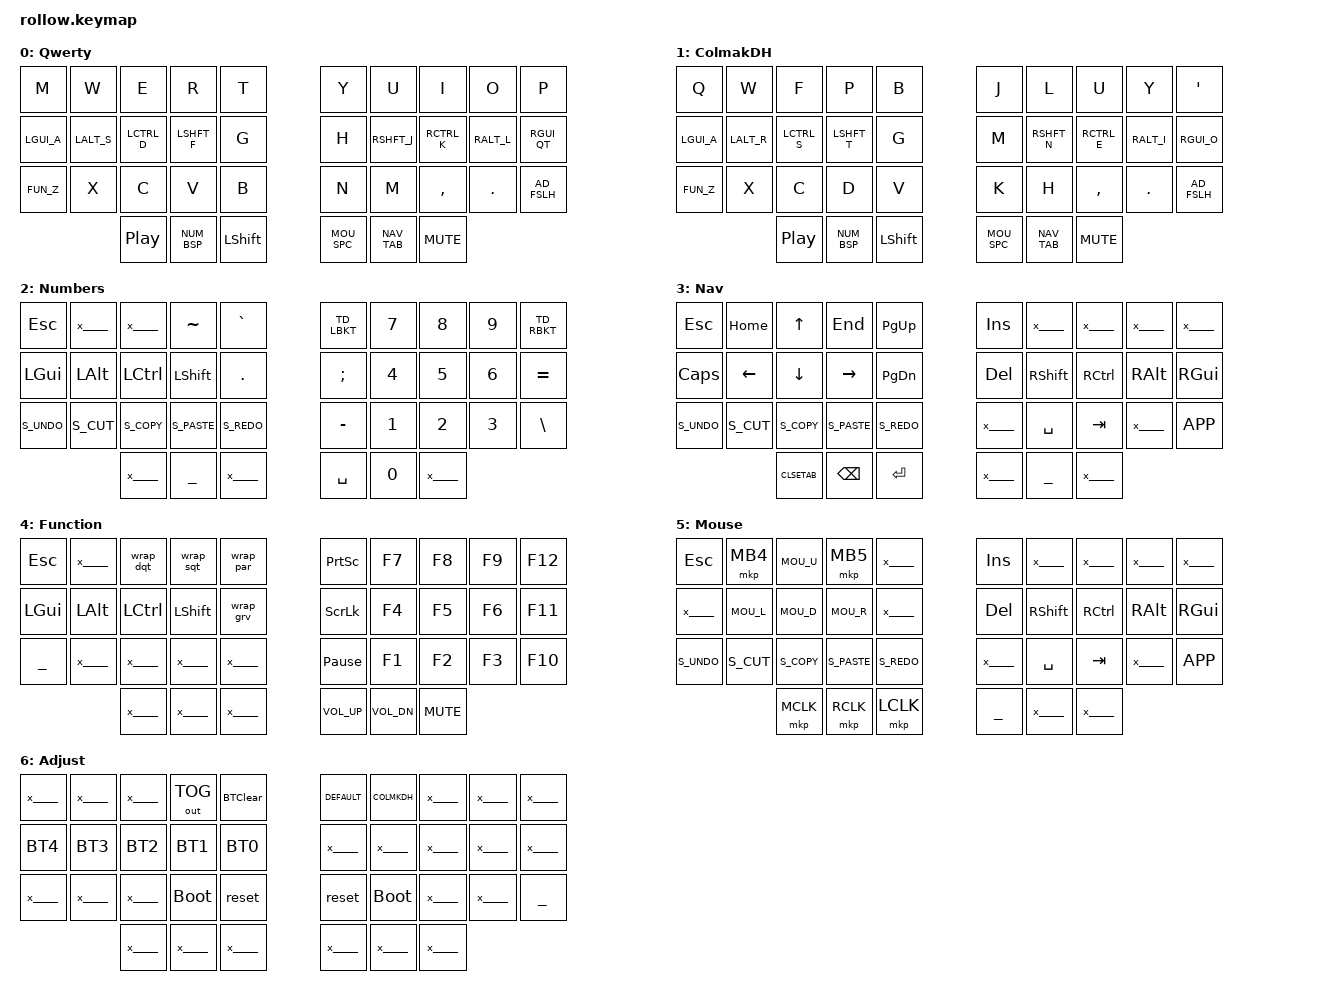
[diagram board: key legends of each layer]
/*
 * Copyright (c) 2020 The ZMK Contributors
 *
 * SPDX-License-Identifier: MIT
 */

#include "../T4CORUN/t4corun.dtsi"

/ {
        chosen {
                zmk,matrix_transform = &five_column_transform;
	};

        behaviors {
        };


        keymap {
                compatible = "zmk,keymap";

                default_layer {

                /*
                *
                *   ,----------------------------------.    ,----------------------------------.
                *   |   Q  |   W  |   E  |   R  |   T  |    |   Y  |   U  |   I  |   O  |   P  |
                *   +------+------+------+------+------|    +------+------+------+------+------+
                *   |   A  |   S  |   D  |   F  |   G  |    |   H  |   J  |   K  |   L  |   '  |
                *   +------+------+------+------+------|    +------+------+------+------+------+
                *   |FUN_Z |   X  |   C  |   V  |   B  |    |   N  |   M  |   ,  |   .  |ADJ_/ |
                *   `------+------+------+------+------+    +------+------+------+------+------'
                *                 |plypau|NUMBSP| Shft |    |MOUSPC|NAVTAB| mute |
                *                 `------+------+------'    `------+------+------'
                *
                *   Encoder Left: Up <-> Down
                *   Encoder Right: Left <-> Right
                */

                        label = "Qwerty";
                        
                        bindings = <
                                &kp M           &kp W           &kp E           &kp R           &kp T           &kp Y           &kp U           &kp I           &kp O           &kp P
                                LGUI_A          LALT_S          LCTRL_D         LSHFT_F         &kp G           &kp H           RSHFT_J         RCTRL_K         RALT_L          RGUI_QT
                                FUN_Z           &kp X           &kp C           &kp V           &kp B           &kp N           &kp M           &kp COMMA       &kp DOT         AD_FSLH
                                                                &kp C_PP        NUM_BSP         &kp LSHFT       MOU_SPC         NAV_TAB         &kp C_MUTE
                        >;

                        sensor-bindings = <&inc_dec_mwh SCROLL_DOWN SCROLL_UP &inc_dec_mwh SCROLL_RIGHT SCROLL_LEFT>;
                };

                colemakdh_layer {

                /*
                *
                *   ,----------------------------------.    ,----------------------------------.
                *   |   Q  |   W  |   F  |   P  |   B  |    |   J  |   L  |   U  |   Y  |   '  |
                *   +------+------+------+------+------|    +------+------+------+------+------+
                *   |   A  |   R  |   S  |   T  |   G  |    |   M  |   N  |   E  |   I  |   O  |
                *   +------+------+------+------+------|    +------+------+------+------+------+
                *   |FUN_Z |   X  |   C  |   D  |   V  |    |   K  |   H  |   ,  |   .  |ADJ_/ |
                *   `------+------+------+------+------+    +------+------+------+------+------'
                *                 |plypau|NUMBSP| Shft |    |MOUSPC|NAVTAB| mute |
                *                 `------+------+------'    `------+------+------'
                *
                *   Encoder Left: Up <-> Down
                *   Encoder Right: Left <-> Right
                */

                        label = "ColmakDH";

                        bindings = <
                                &kp Q           &kp W           &kp F           &kp P           &kp B           &kp J           &kp L           &kp U           &kp Y           &kp SQT
                                LGUI_A          LALT_R          LCTRL_S         LSHFT_T         &kp G           &kp M           RSHFT_N         RCTRL_E         RALT_I          RGUI_O
                                FUN_Z           &kp X           &kp C           &kp D           &kp V           &kp K           &kp H           &kp COMMA       &kp DOT         AD_FSLH
                                                                &kp C_PP        NUM_BSP         &kp LSHFT       MOU_SPC         NAV_TAB         &kp C_MUTE
                        >;

                        sensor-bindings = <&inc_dec_kp DOWN UP &inc_dec_kp RIGHT LEFT>;
                };

                number_layer {

                /*
                *
                *   ,----------------------------------.    ,----------------------------------.
                *   | Esc  |      |      |   ~  |   `  |    | tLBKT|   7  |   8  |   9  | tRBKT|
                *   +------+------+------+------+------|    +------+------+------+------+------+
                *   | GUI  | Alt  | Ctrl | Shft |   .  |    |   ;  |   4  |   5  |   6  |   =  |
                *   +------+------+------+------+------|    +------+------+------+------+------+
                *   | Undo | Cut  | Copy | Pste | Redo |    |   -  |   1  |   2  |   3  |   \  |
                *   `------+------+------+------+------+    +------+------+------+------+------'
                *                 |      |LyrTap|      |    | Spc  |   0  |      |
                *                 `------+------+------'    `------+------+------'
                *
                *   Encoder Left: x <-> x
                *   Encoder Right: Backspace <-> Del
                */

                        label = "Numbers";

                        bindings = <
                                &kp ESC         _____x_____     _____x_____     &kp TILDE       &kp GRAVE       &TD_LBKT        &kp N7          &kp N8          &kp N9          &TD_RBKT
                                &kp LGUI        &kp LALT        &kp LCTRL       &kp LSHFT       &kp DOT         &kp SEMI        &kp N4          &kp N5          &kp N6          &kp EQUAL
                                S_UNDO          S_CUT           S_COPY          S_PASTE         S_REDO          &kp MINUS       &kp N1          &kp N2          &kp N3          &kp BSLH
                                                                _____x_____     ___________     _____x_____     &kp SPACE       &kp N0          _____x_____
                        >;

                        sensor-bindings = <&inc_dec_kp &none &none &inc_dec_kp DEL BSPC>;
                };

                nav_layer {

                /*
                *
                *   ,----------------------------------.    ,----------------------------------.
                *   | Esc  | Home | Up   | End  | PgUp |    | Ins  |      |      |      |      |
                *   +------+------+------+------+------|    +------+------+------+------+------+
                *   | Caps | Left | Down | Right| PgDn |    | Del  | Shft | Ctrl | Alt  | GUI  |
                *   +------+------+------+------+------|    +------+------+------+------+------+
                *   | Undo | Cut  | Copy | Pste | Redo |    |      | Spc  | Tab  |      | App  |
                *   `------+------+------+------+------+    +------+------+------+------+------'
                *                 | close| Bpsc | Ent  |    |      |LyrTap|      |
                *                 `------+------+------'    `------+------+------'
                *
                *   Encoder Left: Previous Browser Tab <-> Next Browser Tab
                *   Encoder Right: x <-> x
                */

                        label = "Nav";

                        bindings = <
                                &kp ESC         &kp HOME        &kp UP          &kp END         &kp PG_UP       &kp INS         _____x_____     _____x_____     _____x_____     _____x_____
                                &kp CAPS        &kp LEFT        &kp DOWN        &kp RIGHT       &kp PG_DN       &kp DEL         &kp RSHFT       &kp RCTRL       &kp RALT        &kp RGUI
                                S_UNDO          S_CUT           S_COPY          S_PASTE         S_REDO          _____x_____     &kp SPACE       &kp TAB         _____x_____     &kp K_APP
                                                                CLSETAB         &kp BSPC        &kp ENTER       _____x_____     ___________     _____x_____
                            >;

                        sensor-bindings = <&inc_dec_kp LC(TAB) LC(LS(TAB)) &inc_dec_kp &none &none>;
                };

                function_layer {

                /*
                *
                *   ,----------------------------------.    ,----------------------------------.
                *   | Esc  |      | wdqt | wsqt | wpar |    |PrtScr|  F7  |  F8  |  F9  | F12  |
                *   +------+------+------+------+------|    +------+------+------+------+------+
                *   | GUI  | Alt  | Ctrl | Shft | wgrv |    |ScrLck|  F4  |  F5  |  F6  | F11  |
                *   +------+------+------+------+------|    +------+------+------+------+------+
                *   |LyrTap|      |      |      |      |    |PauBrk|  F1  |  F2  |  F3  | F10  |
                *   `------+------+------+------+------+    +------+------+------+------+------'
                *                 |      |      |      |    | Vol- | Vol+ | mute |
                *                 `------+------+------'    `------+------+------'
                *
                *   Encoder Left: previous song <-> next song
                *   Encoder Right: Volume Down <-> Volume Up
                */

                        label = "Function";

                        bindings = <
                                &kp ESC         _____x_____     &wrap_dqt       &wrap_sqt       &wrap_par       &kp PSCRN       &kp F7          &kp F8          &kp F9          &kp F12
                                &kp LGUI        &kp LALT        &kp LCTRL       &kp LSHFT       &wrap_grv       &kp SLCK        &kp F4          &kp F5          &kp F6          &kp F11
                                ___________     _____x_____     _____x_____     _____x_____     _____x_____     &kp PAUSE_BREAK &kp F1          &kp F2          &kp F3          &kp F10
                                                                _____x_____     _____x_____     _____x_____     &kp C_VOL_UP    &kp C_VOL_DN    &kp C_MUTE
                        >;

                        sensor-bindings = <&inc_dec_kp C_NEXT C_PREV &inc_dec_kp C_VOL_UP C_VOL_DN>;
                };

                mou_layer {

                /*
                *
                *   ,----------------------------------.    ,----------------------------------.
                *   | Esc  | back | MouU | fwd  |      |    | Ins  |      |      |      |      |
                *   +------+------+------+------+------|    +------+------+------+------+------+
                *   |      | MouL | MouD | MouR |      |    | Del  | Shft | Ctrl | Alt  | GUI  |
                *   +------+------+------+------+------|    +------+------+------+------+------+
                *   | Undo | Cut  | Copy | Pste | Redo |    |      | Spc  | Tab  |      | App  |
                *   `------+------+------+------+------+    +------+------+------+------+------'
                *                 | MMB  | RMB  | LMB  |    |LyrTap|      |      |
                *                 `------+------+------'    `------+------+------'
                *
                *   Encoder Left: Previous Browser Tab <-> Next Browser Tab
                *   Encoder Right: x <-> x
                */

                        label = "Mouse";

                        bindings = <
                                &kp ESC         &mkp MB4        MOU_U           &mkp MB5        _____x_____     &kp INS         _____x_____     _____x_____     _____x_____     _____x_____
                                _____x_____     MOU_L           MOU_D           MOU_R           _____x_____     &kp DEL         &kp RSHFT       &kp RCTRL       &kp RALT        &kp RGUI
                                S_UNDO          S_CUT           S_COPY          S_PASTE         S_REDO          _____x_____     &kp SPACE       &kp TAB         _____x_____     &kp K_APP
                                                                &mkp MCLK       &mkp RCLK       &mkp LCLK       ___________     _____x_____     _____x_____
                            >;

                        sensor-bindings = <&inc_dec_mwh SCROLL_DOWN SCROLL_UP &inc_dec_kp &none &none>;
                };

                adjust_layer {

                /*
                *
                *   ,----------------------------------.    ,----------------------------------.
                *   |      |      |      |OutTog|BT Clr|    |QWERTY|CLMKDH|      |      |      |
                *   +------+------+------+------+------|    +------+------+------+------+------+
                *   | BT4  | BT3  | BT2  | BT1  | BT0  |    |      |      |      |      |      |
                *   +------+------+------+------+------|    +------+------+------+------+------+
                *   |      |      |      | boot |reset |    |reset |boot  |      |      |LyrTap|
                *   `------+------+------+------+------+    +------+------+------+------+------'
                *                 |      |      |      |    |      |      |      |
                *                 `------+------+------'    `------+------+------'
                *
                *   Encoder Left: x <-> x
                *   Encoder Right: x <-> x
                */

                        label = "Adjust";

                        bindings = <
                                _____x_____     _____x_____     _____x_____     &out OUT_TOG    BTClear         DEFAULT         COLMKDH         _____x_____     _____x_____     _____x_____
                                BT4             BT3             BT2             BT1             BT0             _____x_____     _____x_____     _____x_____     _____x_____     _____x_____
                                _____x_____     _____x_____     _____x_____     &bootloader     &reset          &reset          &bootloader     _____x_____     _____x_____     ___________
                                                                _____x_____     _____x_____     _____x_____     _____x_____     _____x_____     _____x_____
                        >;

                        sensor-bindings = <&inc_dec_kp &none &none &inc_dec_kp &none &none>;
                };
        };
};
